# TC37XPD register map
Vendor: Infineon; Series: ATVMC; File version: 100
CPU: other r0p0, little endian, MPU, FPU, vendor SysTick, 4 interrupt priority bits
Registers are 32-bit, read-write, reset 0x0 unless marked. A register's access mark holds for its fields unless they carry their own. Offsets are from the block's base; [hi:lo] are bit positions; {n}, {i} and the like mark numbered series.

## PMS (part 1 of 3)
Base 0xF0248000
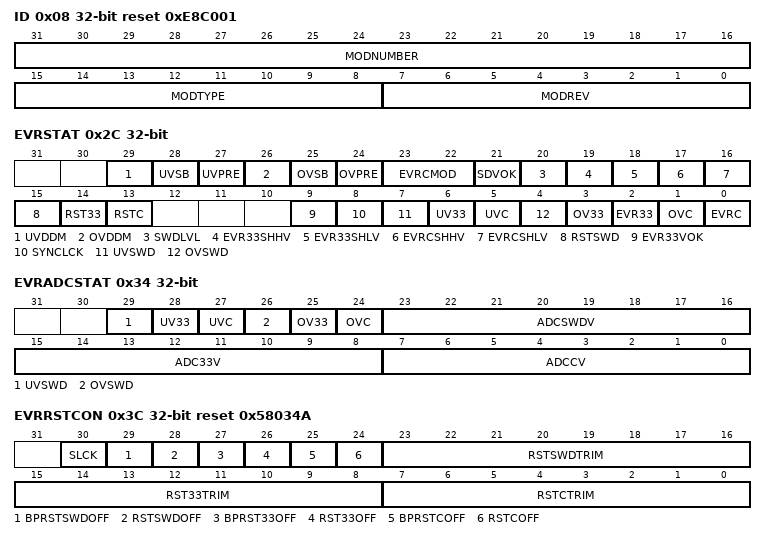
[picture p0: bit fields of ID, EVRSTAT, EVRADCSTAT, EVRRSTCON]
0x08 ID ro reset 0xE8C001 — Identification Register resetvalue={Application Reset:0x0E8C001}
  [31:16] MODNUMBER — Module Number MODNUMBER. This bit field defines the module identification number. The identification number for the PMS is 00E8 H .
  [15:8] MODTYPE — Module Type MODTYPE. This bit field is fixed coded as C0 H . It defines a 32 bit module.
  [7:0] MODREV — Module Revision Number MODREV. This bit field indicates the revision number of the PMS module. This is intended as a continuous numbering scheme defined by Design.
0x2C EVRSTAT ro — EVR Status Register resetvalue={LVD Reset:0x0,Cold PORST:0x0}
  [29] UVDDM — ADC VDDM Supply Under voltage event flag UVDDM. This bit is set if VDDM ADC supply secondary voltage monitor recognizes an under voltage event. An alarm is raised to the SMU.
  [28] UVSB — Standby Supply or VEVRSB Under voltage event flag UVSB. This bit is set if VEVRSB supply secondary voltage monitor recognizes an under voltage event. An alarm is raised to the SMU.
  [27] UVPRE — Pre Regulator VDDPD Under voltage event flag UVPRE. This bit is set if VDDPD supply secondary voltage monitor recognizes an under voltage event. An alarm is raised to the SMU.
  [26] OVDDM — ADC VDDM Supply Over voltage event flag OVDDM. This bit is set if VDDM ADC supply secondary voltage monitor recognizes an over voltage event. An alarm is raised to the SMU.
  [25] OVSB — Standby Supply or VEVRSB Over voltage event flag OVSB. This bit is set if VEVRSB supply secondary voltage monitor recognizes an over voltage event. An alarm is raised to the SMU.
  [24] OVPRE — Pre Regulator VDDPD Over voltage event flag OVPRE. This bit is set if VDDPD supply secondary voltage monitor recognizes an over voltage event. An alarm is raised to the SMU.
  [23:22] EVRCMOD — EVRC Mode EVRCMOD. This bit indicates the current operation mode of LC PWM LPM STRT. Depending on whether EVRC is activated the status bit is consequently updated. status mode o
  [21] SDVOK — EVRC Regulator Voltage OK status SDVOK. This bit is set by the EVRC voltage OK detector to indicate that the new regulator output value has been reached. This bit is reset incase EVRTRIM. SDVOUTSEL or SDVOUTTRIM values are adapted to scale core voltage and is set when the new output setpoint is reached. This bit is also reset incase droop compensation is requested before a load jump event. A time out period of x 160 us shall be waited when polling SDVOK bit. status voltok o
  [20] SWDLVL — VEXT External Supply Level Status SWDLVL. This bit indicates that the VEXT voltage has dropped below 4 160 V to indicate EVRC parameter switch to differentiate 5V or 3.3V external supply. A hysteresis of 120 160 mV is implemented on this detector. drv low vdd . The primary SWD ADC monitor value is used for EVRC SWDLVL comparator.
  [19] EVR33SHHV — Short to supply EVR33SHHV. This bit is set if a short condition to supply has been detected. The measured EVR33 output exceeds the allowed supply range and the upper gate drive threshold voltage driving P ch. MOSFET VGATEL 4 9V is reached.
  [18] EVR33SHLV — Short to ground EVR33SHLV. This bit is set if a short condition to ground has been detected. The measured EVR33 output is below the operational supply range and the lower gate drive threshold voltage driving P ch. MOSFET VGATEL 0 1V is reached.
  [17] EVRCSHHV — Short to supply EVRCSHHV. This bit is set if a short condition to supply has been detected. The measured EVRC output exceeds the allowed supply range and the lower controller limits are reached. The feature is supported only during closed loop operation or EVRCMOD 160 160 00b. evr sd short to hv
  [16] EVRCSHLV — Short to ground EVRCSHLV. This bit is set if a short condition to ground has been detected. The measured EVRC output is below the operational supply range and the upper controller limits are reached.The feature is supported only during closed loop operation or EVRCMOD 160 160 00b. evr sd short to lv
  [15] RSTSWD — EVR SWD Reset Trigger RSTSWD
  [14] RST33 — EVR33 Reset Trigger RST33
  [13] RSTC — EVRC Reset Trigger RSTC
  [9] EVR33VOK — EVR33 Regulator Voltage OK status EVR33VOK. This bit is set after the soft ramp up time of the EVR33 voltage OK ramp detector has elapsed and is not based on the measured VDDP3 voltage at the end of ramp phase..
  [8] SYNCLCK — EVRC Synchronization Input Locked status sd sync in locked o SYNCLCK. This bitfield indicates the current synchronization status of EVRC SMPS regulator to external DCDCSYNCI input signal. When the EVRC switching frequency edge is locked to the synchronization input the SYNCLCK bit is set to HIGH indicating the locked state. When the synchronization is lost owing to frequency deviations beyond MAXDEV or the feature is disabled via SYNCEN the SYNCLCK bit is set to LOW. This EVRC Synchronization status is indicated in EVRSDSTAT0.SYNCLCK status bits.
  [7] UVSWD — VEXT Under voltage event flag UVSWD. This bit is set if VEXT secondary voltage monitor recognizes an under voltage event. An alarm is raised to the SMU and the status bit remains set until violation disappears.
  [6] UV33 — VDDP3 Under voltage event flag UV33. This bit is set if VDDP3 secondary voltage monitor recognizes a under voltage event. An alarm is raised to the SMU and the status bit remains set until violation disappears.
  [5] UVC — VDD Under voltage event flag UVC. This bit is set if VDD secondary voltage monitor recognizes a under voltage event. An alarm is raised to the SMU and the status bit remains set until violation disappears.
  [4] OVSWD — VEXT Over voltage event flag OVSWD. This bit is set if VEXT secondary voltage monitor recognizes an over voltage event. An alarm is raised to the SMU and the status bit remains set until violation disappears.
  [3] OV33 — VDDP3 Over voltage event flag OV33. This bit is set if VDDP3 secondary voltage monitor recognizes a over voltage event. An alarm is raised to the SMU and the status bit remains set until violation disappears.
  [2] EVR33 — EVR33 status EVR33. This bit is set if the internal EVR33 LDO regulator is active. EVR33 is activated if HWCFG 1 pin level is latched high during start up phase. The bit reflects the EVR33 enable bit provided from PMS to PID.
  [1] OVC — VDD Over voltage event flag OVC. This bit is set if VDD secondary voltage monitor recognizes a over voltage event. An alarm is raised to the SMU and the status bit remains set until violation disappears.
  [0] EVRC — EVRC status EVRC. This bit is set if the internal EVRC regulator is currently active. EVRC is activated if HWCFG 2 pin level is latched high during start up phase. The bit reflects the DCDC regulator enable bit provided from PMS to DCDC.
0x34 EVRADCSTAT ro — EVR Primary ADC Status Register resetvalue={LVD Reset:0x0}
  [29] UVSWD — Supply Watchdog SWD or VEXT Under voltage event flag UVSWD. This bit is set if VEXT primary voltage monitor recognizes an under voltage event. An alarm is raised to the HSM and SMU.
  [28] UV33 — EVR33 Regulator or VDDP3 Under voltage event flag UV33. This bit is set if VDDP3 primary voltage monitor recognizes a under voltage event. An alarm is raised to the HSM and SMU.
  [27] UVC — EVRC Regulator or VDD Under voltage event flag UVC. This bit is set if VDD primary voltage monitor recognizes a under voltage event. An alarm is raised to the HSM and SMU.
  [26] OVSWD — Supply Watchdog SWD or VEXT Over voltage event flag OVSWD. This bit is set if VEXT primary voltage monitor recognizes an over voltage event. An alarm is raised to the HSM and SMU.
  [25] OV33 — EVR33 Regulator or VDDP3 Over voltage event flag OV33. This bit is set if VDDP3 primary voltage monitor recognizes a over voltage event. An alarm is raised to the HSM and SMU.
  [24] OVC — EVRC Regulator or VDD Over voltage event flag OVC. This bit is set if VDD primary voltage monitor recognizes a over voltage event. An alarm is raised to the HSM and SMU.
  [23:16] ADCSWDV — ADC VEXT Supply Conversion Result ADCSWDV. This bit field contains the last filtered conversion result of the ADC measurement of the external VEXT 3.3V xa0 xa0 5V supply by the Primary Monitor. VIN xa0 xa0 1.050 ADCSWDV xa0 xa0 LSB xa0 V xa0 LSB 20 xa0 mV Eg. 5 V C6
  [15:8] ADC33V — ADC VDDP3 Voltage Conversion Result ADC33V. This bit field contains the last filtered conversion result of the ADC measurement of the VDDP3 xa0 xa0 EVR33 supply by the Primary Monitor. VIN xa0 xa0 0.9375 ADC33V xa0 xa0 LSB xa0 V LSB 15 xa0 mV Eg. 3.3 V 9E
  [7:0] ADCCV — ADC VDD Core Voltage Conversion Result ADCCV. This bit field contains the last filtered conversion result of the ADC measurement of the VDD xa0 xa0 EVRC supply by the Primary Monitor. VIN xa0 xa0 0.7125 ADCCV xa0 xa0 LSB xa0 V LSB 5 xa0 mV Eg. 1.25 V 6C
0x3C EVRRSTCON access per field reset 0x58034A (reset mask 0xFFFA03FE) — EVR Reset Control Register resetvalue={LVD Reset:0x597F4A,Cold PORST:0x597F4A,After SSW execution:0x5C834B}
  [30] SLCK rw — HSM Security Lock SLCK. If this bit is set all other bits in this register can no longer be written. Write requests to other bits when SLCK is set will trigger an SLCK access error alarm.This bit can not by cleared by software. SLCK bit can only be set by an access from the HSM master TAG 160 160 000011 B . A set operation performed by any other master or software is ignored and the bit is kept as cleared.
  [29] BPRSTSWDOFF wo — Bit Protection RSTSWDOFF BPRSTSWDOFF. Setting this bit enables that bit RSTSWDOFF can be changed in this write operation. This bit is read as zero.
  [28] RSTSWDOFF rw — VEXT Reset Enable RSTSWDOFF. This bit can only be changed if bit BPRSTSWDOFF is set in parallel. RSTSWDOFF is intended to be used only for internal test purposes and the primary reset generation is not to be disabled in customer application.
  [27] BPRST33OFF wo — Bit Protection RST33OFF BPRST33OFF. Setting this bit enables that bit RST33OFF can be changed in this write operation. This bit read also as zero.
  [26] RST33OFF rw — VDDP3 Reset Enable RST33OFF. This bit can only be changed if bit BPRST33OFF is set in parallel. The VDDP3 reset is disabled by application to support voltage drop up to nominal 3.0 160 V during cranking. RST33OFF is intended to be used only for internal test purposes and the primary reset generation is not to be disabled in customer application.
  [25] BPRSTCOFF wo — Bit Protection RSTCOFF BPRSTCOFF. Setting this bit enables that bit RSTCOFF can be changed in this write operation. This bit is read as zero.
  [24] RSTCOFF rw — VDD Reset Enable RSTCOFF. This bit can only be changed if bit BPRSTCOFF is set in parallel. RSTCOFF is intended to be used only for internal test purposes and the primary reset generation is not to be disabled in customer application.
  [23:16] RSTSWDTRIM rw — VEXT Supply Reset Trim Value RSTSWDTRIM. This bit field selects the hard reset generation level of the external VEXT supply rail. This bitfield is trimmed by Firmware. RSTSWDTRIM VDDx 1050 mV LSB if RSTSWDPTRIM 0 VEXTPRIUV 1050 mV LSB RSTSWDTRIM LSB RSTSWDPTRIM signed value LSB 20 mV
  [15:8] RST33TRIM rw — VDDP3 Supply Reset Trim Value RST33TRIM. This bit field selects the hard reset generation level of VDDP3 supply rail. This bit field is trimmed by Firmware. RST33TRIM VDDx 937.5 mV LSB if RST33PTRIM 0 VDDP3PRIUV 160 160 937.5 mV LSB RST33TRIM LSB RST33PTRIM signed value LSB 15 mV
  [7:0] RSTCTRIM rw — VDD Supply Reset Trim Value RSTCTRIM. This bit field selects the hard reset generation level of VDD supply rail. This bit field is trimmed by Firmware. RSTCTRIM 160 160 VDDx 712.5 mV LSB if RSTCPTRIM 0 VDDPRIUV 160 160 712.5 mV LSB RSTCTRIM LSB RSTCPTRIM signed value LSB 5 mV
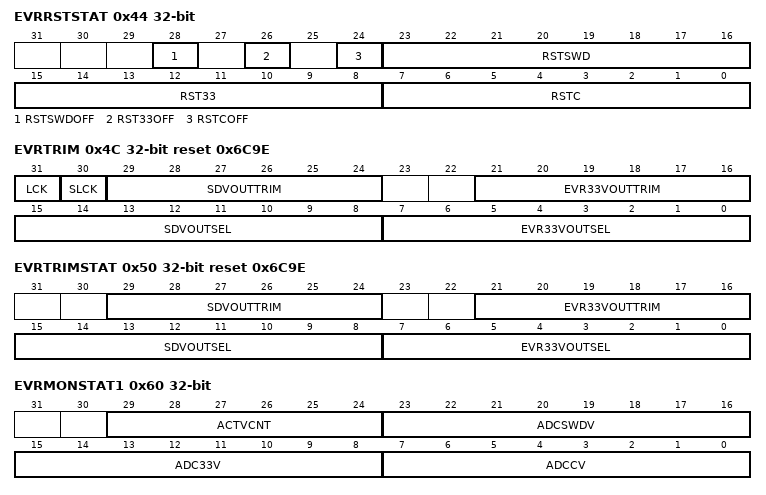
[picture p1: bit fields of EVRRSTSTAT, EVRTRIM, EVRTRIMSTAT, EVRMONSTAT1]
0x44 EVRRSTSTAT ro — EVR Reset Status Register resetvalue={LVD Reset:0x0,Cold PORST:0x0}
  [28] RSTSWDOFF — EVR SWD Reset Enable RSTSWDOFF. The value is updated via PMS EVRRSTCON .RSTSWDOFF register bit.
  [26] RST33OFF — EVR33 Reset Enable Status RST33OFF. The value is updated via PMS EVRRSTCON .RST33OFF register bit.
  [24] RSTCOFF — EVRC Reset Enable Status RSTCOFF. The value is updated via PMS EVRRSTCON .RSTCOFF register bit.
  [23:16] RSTSWD — VEXT Supply Reset Value Status RSTSWD. This bit field indicates the actual cold PORST reset trim setpoint for 5 160 V supply rail used by the Primary monitors. The value is updated via PMS EVRRSTCON .RSTSWDTRIM and PMS EVRRSTCON2 . RSTSWDPTRIM register. RSTSWD RSTSWDTRIM RSTSWDPTRIM signed value RSTSWD range 160 160 0 up to 255 VEXTPRIUV 1050 mV LSB RSTSWD LSB 20 mV
  [15:8] RST33 — VDDP3 Supply Reset Value Status RST33. This bit field indicates the actual cold PORST reset trim setpoint for 3.3 160 V supply rail used by the Primary monitors. The value is updated via PMS EVRRSTCON .RST33TRIM and PMS EVRRSTCON2 .RST33PTRIM register. RST33 RST33TRIM RST33PTRIM signed value RST33 range 160 160 0 up to 255 VDDP3PRIUV 937.5 mV LSB RST33 LSB 15 mV
  [7:0] RSTC — VDD Supply Reset Value Status RSTC. This bit field indicates the actual cold PORST reset trim setpoint for core voltage supply rail used by the Primary monitors. The value is updated via PMS EVRRSTCON .RSTCTRIM and PMS EVRRSTCON2 .RSTCPTRIM register. RSTC RSTCTRIM RSTCPTRIM signed value RSTC range 160 160 0 up to 255 VDDPRIUV 712.5 mV LSB RSTC LSB 5 mV
0x4C EVRTRIM access per field reset 0x6C9E (reset mask 0x7FFFFFFF) — EVR Trim Control Register resetvalue={LVD Reset:0x080006C9E,Cold PORST:0x080006C9E,After SSW execution:0x6C9E}
  [31] LCK ro — Lock Status LCK. This bit indicates if the register can be updated with a new value or if the register is locked and a write action from the bus side has no effect. When EVRSDCTRL0.UP bit is set to 1 register is locked for shadow register update and LCK bit is set to 1. Once shadow register update is done the lock is released and LCK bit is set to 0.
  [30] SLCK rw — HSM Security Lock SLCK. If this bit is set all other bits in this register can no longer be written. Write requests to other bits when SLCK is set will trigger an SLCK access error alarm.This bit can not by cleared by software. SLCK bit can only be set by an access from the HSM master TAG 160 160 000011 B . A set operation performed by any other master or software is ignored and the bit is kept as cleared.
  [29:24] SDVOUTTRIM rw — EVRC Regulator Output Voltage Trim Value vtrim trim i SDVOUTTRIM. The 6 bit ADC BIST trimming value offset added to the EVRC output level value installed by firmware from the flash. The reaching of the new setpoint is indicated via EVRSTAT.SDVOK bits VDD Setpoint SDVOUTSEL SDVOUTTRIM signed value SDVOUTTRIM RANGE 32 to 31 LSB LSB 5 mV This register bitfield requires a parameter update via EVRSDCTRL0.UP for transfer to SMPS shadow register.
  [21:16] EVR33VOUTTRIM rw — EVR33 Regulator Output Voltage Trim Value EVR33VOUTTRIM. The 6 bit ADC BIST trimming value offset added to the EVR33 output level value installed by firmware from the flash. This field is meant for trimming during production tests. VDDP3 Setpoint EVR33VOUTSEL EVR33VOUTTRIM signed value EVR33OUTTRIM RANGE 32 to 31 LSB LSB 15 mV
  [15:8] SDVOUTSEL rw — EVRC Regulator Output Voltage Target Value SDVOUTSEL. The VDD output level of the Step down regulator. vosel target i 1.25 V 6C 108 SDVOUTSEL VDD 712.5 mV LSB VDD 712.5 mV LSB SDVOUTSEL LSB 5 mV. This register bitfield requires a parameter update via EVRSDCTRL0.UP for transfer to EVRC SMPS shadow register. The reaching of the new target value is indicated via EVRSTAT.SDVOK bit.
  [7:0] EVR33VOUTSEL rw — EVR33 Regulator Output Voltage Target Value EVR33VOUTSEL. The VDDP3 output level of the EVR33 LDO regulator. The ramp up completion to the new target value is indicated via EVRSTAT.EVR33VOK bit. The EVR33VOUTSEL EVR33VOUTTRIM setpoint value shall be programmed between 0x24 and 0xDA for valid closed loop PID regulator function. 3.3 V 9E 158 EVR33VOUTSEL VDDP3 937.5 mV LSB VDDP3 937.5 mV LSB EVR33VOUTSEL LSB 15 mV
0x50 EVRTRIMSTAT ro reset 0x6C9E — EVR Trim Status Register resetvalue={LVD Reset:0x6C9E,Cold PORST:0x6C9E}
  [29:24] SDVOUTTRIM — EVRC Regulator Output Voltage Trim Value vtrim trim o SDVOUTTRIM. This bit field indicates the 5 bit ADC BIST trimming value offset added to the EVRC output level value installed by firmware from flash configuration sector as configured in EVTRIM.SDVOUTTRIM.
  [21:16] EVR33VOUTTRIM — EVR33 Regulator Output Voltage Trim Value EVR33VOUTTRIM. This bit field indicates the 6 bit ADC BIST trimming value offset added to the EVR33 output level value installed by firmware from flash configuration sector if production trimming is required.
  [15:8] SDVOUTSEL — EVRC Regulator Output Voltage Target Value SDVOUTSEL. This bit field indicates the EVRC output level of the Step down regulator as configured in EVTRIM.SDVOUTSEL. vosel target o
  [7:0] EVR33VOUTSEL — EVR33 Regulator Output Voltage Target Value EVR33VOUTSEL. This bitfield indicates EVR33 output target value as configured in EVTRIM.EVR33VOUTSEL.
0x60 EVRMONSTAT1 ro — EVR Secondary ADC Status Register 1 resetvalue={LVD Reset:0x0,Cold PORST:0x0}
  [29:24] ACTVCNT — Secondary Monitor Activity Counter ACTVCNT. This bit field cumulatively counts the end of conversion signals in a single Secondary Monitor Background Scan over all channels and respective filter configurations. The total number of conversions ConvTot 8721 ChX ChXFIL . The counter is reset to 0 on a ConvTot overflow.
  [23:16] ADCSWDV — VEXT Supply Secondary ADC Conversion Result ADCSWDV. This bit field contains the last conversion result of the ADC measurement of the external VEXT 3.3V 160 160 5V supply by the Secondary Monitor. This bitfield is updated if secondary over or under voltage monitoring is activated via EVRMONCTRL.SWDxxMOD. The update of the result is taking place at 6 160 160 160 12 160 160 active channels 160 160 fBACK 4 160 clock cycles. VIN 160 160 LSB 160 160 ADCx 1 160 160 LSB 23.077 160 mV Full Range 160 160 5861 160 mV E.g. 5.01 160 V DA 160 160 160 160 160 160 3.3 160 V 90
  [15:8] ADC33V — VDDP3 Supply Secondary ADC Conversion Result ADC33V. This bit field contains the last conversion result of the ADC measurement of the VDDP3 160 160 EVR33 supply by the Secondary Monitor. This bitfield is updated if secondary over or under voltage monitoring is activated via EVRMONCTRL.EVR33xxMOD. The update of the result is taking place at 6 160 160 160 12 160 160 active channels 160 160 fBACK 4 160 clock cycles. VIN 160 160 LSB 160 160 ADCx 1 160 160 Ideal LSB 15.00 160 mV Full Range 160 160 3810 160 mV E.g. 3.30 160 V DD
  [7:0] ADCCV — VDD Supply Secondary ADC Conversion Result ADCCV. This bit field contains the last conversion result of the ADC measurement of the VDD 160 160 EVRC supply by the Secondary Monitor. This bitfield is updated if secondary over or under voltage monitoring is activated via EVRMONCTRL.EVRCxxMOD. The update of the result is taking place at 6 160 160 160 12 160 160 active channels 160 160 fBACK 4 160 clock cycles. VIN 160 160 LSB 160 160 ADCx 1 160 160 Ideal LSB 5.7692 160 mV Full Range 160 160 1465 160 mV E.g. 1.25 160 V DA
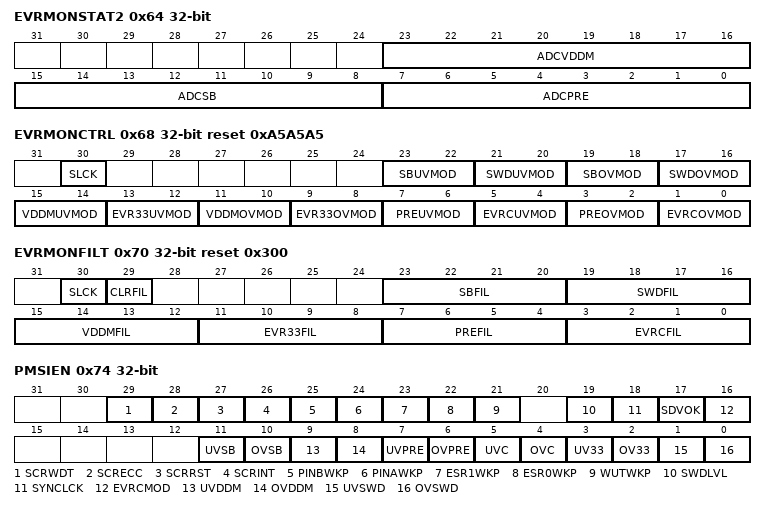
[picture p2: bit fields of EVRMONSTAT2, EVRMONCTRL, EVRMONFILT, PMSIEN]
0x64 EVRMONSTAT2 ro — EVR Secondary ADC Status Register 2 resetvalue={LVD Reset:0x0,Cold PORST:0x0}
  [23:16] ADCVDDM — VDDM Supply Secondary ADC Conversion Result ADCVDDM. This bit field contains the last conversion result of the ADC measurement of the VDDM ADC supply by the Secondary Monitor. This bitfield is updated if secondary over or under voltage monitoring is activated via EVRMONCTRL.VDDMxxMOD. The update of the result is taking place at 6 160 160 160 12 160 160 active channels 160 160 fBACK 4 160 clock cycles. VIN 160 160 LSB 160 160 ADCx 1 160 160 Ideal LSB 23.077 160 mV Full Range 160 160 5861 160 mV E.g. 5.01 160 V DA 160 160 160 160 160 160 3.0 160 V 90
  [15:8] ADCSB — VEVRSB Supply Secondary ADC Conversion Result ADCSB. This bit field contains the last conversion result of the ADC measurement of the external VEVRSB 3.3V 160 160 5V standby supply by the Secondary Monitor. This bitfield is updated if secondary over or under voltage monitoring is activated via EVRMONCTRL.SBxxMOD. The update of the result is taking place at 6 160 160 160 12 160 160 active channels 160 160 fBACK 4 160 clock cycles. VIN 160 160 LSB 160 160 ADCx 1 160 160 Ideal LSB 23.077 160 mV Full Range 160 160 5861 160 mV E.g. 5.01 160 V DA 160 160 160 160 160 160 3.0 160 V 90
  [7:0] ADCPRE — VDDPD Supply Secondary ADC Conversion Result ADCPRE. This bit field contains the last conversion result of the ADC measurement of the VDDPD supply by the Secondary Monitor. This bitfield is updated if secondary over or under voltage monitoring is activated via EVRMONCTRL.PRExxMOD. The update of the result is taking place at 6 160 160 160 12 160 160 active channels 160 160 fBACK 4 160 clock cycles. VIN 160 160 LSB 160 160 ADCx 1 160 160 Ideal LSB 5.7692 160 mV Full Range 160 160 1465 160 mV E.g. 1.25 160 V DA
0x68 EVRMONCTRL reset 0xA5A5A5 — EVR Secondary Monitor Control Register resetvalue={LVD Reset:0x0A5A5A5,Cold PORST:0x0A5A5A5,After SSW execution:0x0A5A5A5}
  [30] SLCK — HSM Security Lock SLCK. If this bit is set all other bits in this register can no longer be written. Write requests to other bits when SLCK is set will trigger an SLCK access error alarm.This bit can not by cleared by software. SLCK bit can only be set by an access from the HSM master TAG 160 160 000011 B . A set operation performed by any other master or software is ignored and the bit is kept as cleared.
  [23:22] SBUVMOD — EVR Standby Supply or VEVRSB Under voltage monitoring mode SBUVMOD. Incase both SBOVMOD 160 160 00 amp SBUVMOD 160 160 00 then ADC conversion for the respective supply rail does not take place.
  [21:20] SWDUVMOD — VEXT Under voltage monitoring mode SWDUVMOD. Incase both SWDOVMOD 160 160 00 amp SWDUVMOD 160 160 00 then ADC conversion for the respective supply rail does not take place.
  [19:18] SBOVMOD — EVR Standby Supply or VEVRSB Over voltage monitoring mode SBOVMOD. Incase both SBOVMOD 160 160 00 amp SBUVMOD 160 160 00 then ADC conversion for the respective supply rail does not take place.
  [17:16] SWDOVMOD — VEXT Over voltage monitoring mode SWDOVMOD. Incase both SWDOVMOD 160 160 00 amp SWDUVMOD 160 160 00 then ADC conversion for the respective supply rail does not take place.
  [15:14] VDDMUVMOD — VDDM ADC Supply Under voltage monitoring mode VDDMUVMOD. Incase both VDDMOVMOD 160 160 00 amp VDDMUVMOD 160 160 00 then ADC conversion for the VDDM supply rail continues to run as used for ADC function.
  [13:12] EVR33UVMOD — VDDP3 Supply Under voltage monitoring mode EVR33UVMOD. Incase both EVR33OVMOD 160 160 00 amp EVR33UVMOD 160 160 00 then ADC conversion for the respective supply rail does not take place.
  [11:10] VDDMOVMOD — VDDM ADC Supply Over voltage monitoring mode VDDMOVMOD. Incase both VDDMOVMOD 160 160 00 amp VDDMUVMOD 160 160 00 then ADC conversion for the VDDM supply rail continues to run as used for ADC function.
  [9:8] EVR33OVMOD — VDDP3 Supply Over voltage monitoring mode EVR33OVMOD. Incase both EVR33OVMOD 160 160 00 amp EVR33UVMOD 160 160 00 then ADC conversion for the respective supply rail does not take place.
  [7:6] PREUVMOD — EVRPR or VDDPD Under voltage monitoring mode PREUVMOD. Incase both PREOVMOD 160 160 00 amp PREUVMOD 160 160 00 then ADC conversion for the respective supply rail does not take place.
  [5:4] EVRCUVMOD — VDD Under voltage monitoring mode EVRCUVMOD. Incase both EVRCOVMOD 160 160 00 amp EVRCUVMOD 160 160 00 then ADC conversion for the respective supply rail does not take place.
  [3:2] PREOVMOD — EVRPR or VDDPD Over voltage monitoring mode PREOVMOD. Incase both PREOVMOD 160 160 00 amp PREUVMOD 160 160 00 then ADC conversion for the respective supply rail does not take place.
  [1:0] EVRCOVMOD — VDD Over voltage monitoring mode EVRCOVMOD. Incase both EVRCOVMOD 160 160 00 amp EVRCUVMOD 160 160 00 then ADC conversion for the respective supply rail does not take place.
0x70 EVRMONFILT reset 0x300 (reset mask 0xFFFEFFFE) — EVR Secondary Monitor Filter Register resetvalue={LVD Reset:0x300,Cold PORST:0x300,After SSW execution:0x10301}
  [30] SLCK — HSM Security Lock SLCK. If this bit is set all other bits in this register can no longer be written. Write requests to other bits when SLCK is set will trigger an SLCK access error alarm.This bit can not by cleared by software. SLCK bit can only be set by an access from the HSM master TAG 160 160 000011 B . A set operation performed by any other master or software is ignored and the bit is kept as cleared.
  [29] CLRFIL — Clear all Spike Filters CLRFIL. To avoid spurious alarms during change of configuration or start up CLRFIL shall be set followed by alarm reconfiguration followed by activation of filter logic by clearing CLRFIL register bit.
  [23:20] SBFIL — VEVRSB Secondary ADC Supply Filter SBFIL
  [19:16] SWDFIL — VEXT Secondary ADC Supply Filter SWDFIL
  [15:12] VDDMFIL — VDDM Secondary ADC Supply Filter VDDMFIL
  [11:8] EVR33FIL — VDDP3 Secondary ADC Supply Filter EVR33FIL
  [7:4] PREFIL — VDDPD Secondary ADC Supply Filter PREFIL
  [3:0] EVRCFIL — VDD Secondary ADC Supply Filter EVRCFIL
0x74 PMSIEN — PMS Interrupt Enable Register resetvalue={LVD Reset:0x0,Cold PORST:0x0}
  [29] SCRWDT — SCRWDT Interrupt enable SCRWDT. Interrupt triggered by SCR to PMS on an internal SCR watchdog timeout error.
  [28] SCRECC — SCRECC Interrupt enable SCRECC. Interrupt triggered by SCR to PMS on an internal RAM double bit ECC error.
  [27] SCRRST — SCRRST Interrupt enable SCRRST. Interrupt triggered by SCR to PMS on an internal SCR software reset.
  [26] SCRINT — SCRINT Interrupt enable SCRINT. Interrupt triggered on a SCRINT event triggered by SCR to PMS to decode information in PMSWCR2.SCRINT register.
  [25] PINBWKP — PINBWKP Interrupt enable PINBWKP. Interrupt triggered on a PINBWKP event.
  [24] PINAWKP — PINAWKP Interrupt enable PINAWKP. Interrupt triggered on a PINAWKP event.
  [23] ESR1WKP — ESR1WKP Interrupt enable ESR1WKP. Interrupt triggered on a ESR1WKP event.
  [22] ESR0WKP — ESR0WKP Interrupt enable ESR0WKP. Interrupt triggered on a ESR0WKP event.
  [21] WUTWKP — WUTWKP Interrupt enable WUTWKP. Interrupt triggered on a WUTCNT underflow event.
  [19] SWDLVL — SWDLVL Interrupt enable SWDLVL. Interrupt triggered on a state change of EVRSTAT.SWDLVL bitfield.
  [18] SYNCLCK — SD SYNCLCK Interrupt enable SYNCLCK. Interrupt triggered on a state change of EVRSTAT.SYNCLCK bitfield.
  [17] SDVOK — SDVOK Interrupt enable SDVOK. Interrupt triggered on EVRSTAT.SDVOK rising edge event.
  [16] EVRCMOD — EVRCMOD Interrupt enable EVRCMOD. Interrupt triggered on a state change of EVRSTAT.EVRCMOD 0 bitfield.
  [11] UVSB — UVSB Interrupt enable UVSB. Interrupt triggered on event as configured in EVRMONCTRL register.
  [10] OVSB — OVSB Interrupt enable OVSB. Interrupt triggered on event as configured in EVRMONCTRL register.
  [9] UVDDM — UVDDM Interrupt enable UVDDM. Interrupt triggered on event as configured in EVRMONCTRL register.
  [8] OVDDM — OVDDM Interrupt enable OVDDM. Interrupt triggered on event as configured in EVRMONCTRL register.
  [7] UVPRE — UVPRE Interrupt enable UVPRE. Interrupt triggered on event as configured in EVRMONCTRL register.
  [6] OVPRE — OVPRE Interrupt enable OVPRE. Interrupt triggered on event as configured in EVRMONCTRL register.
  [5] UVC — UVC Interrupt enable UVC. Interrupt triggered on event as configured in EVRMONCTRL register.
  [4] OVC — OVC Interrupt enable OVC. Interrupt triggered on event as configured in EVRMONCTRL register.
  [3] UV33 — UV33 Interrupt enable UV33. Interrupt triggered on event as configured in EVRMONCTRL register.
  [2] OV33 — OV33 Interrupt enable OV33. Interrupt triggered on event as configured in EVRMONCTRL register.
  [1] UVSWD — UVSWD Interrupt enable UVSWD. Interrupt triggered on event as configured in EVRMONCTRL register.
  [0] OVSWD — OVSWD Interrupt enable OVSWD. Interrupt triggered on event as configured in EVRMONCTRL register.
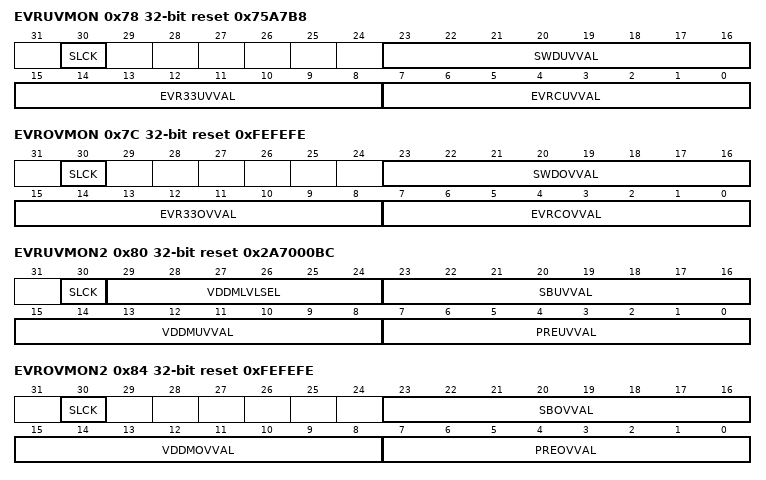
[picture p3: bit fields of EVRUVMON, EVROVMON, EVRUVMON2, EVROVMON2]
0x78 EVRUVMON reset 0x75A7B8 — EVR Secondary Under voltage Monitor Register resetvalue={LVD Reset:0x75A7B8,Cold PORST:0x75A7B8,After SSW execution:0x75A7B8}
  [30] SLCK — HSM Security Lock SLCK. If this bit is set all other bits in this register can no longer be written. Write requests to other bits when SLCK is set will trigger an SLCK access error alarm.This bit can not by cleared by software. SLCK bit can only be set by an access from the HSM master TAG 160 160 000011 B . A set operation performed by any other master or software is ignored and the bit is kept as cleared.
  [23:16] SWDUVVAL — VEXT Supply Secondary Monitor Under voltage threshold SWDUVVAL. This field defines the under voltage threshold level of the external VEXT supply monitor. Ideal Threshold VIN 160 160 LSB 160 160 1 Ideal LSB 23.077 160 mV.
  [15:8] EVR33UVVAL — VDDP3 Supply Secondary Monitor Under voltage threshold EVR33UVVAL. This field defines the under voltage monitoring threshold level of the EVR33 regulator output or VDDP3 supply. Ideal Threshold VIN 160 160 LSB 160 160 1 . Ideal LSB 15.00 160 mV
  [7:0] EVRCUVVAL — VDD Supply Secondary Monitor Under voltage threshold EVRCUVVAL. This field defines the under voltage monitoring threshold level of the EVRC regulator output or VDD supply. Ideal Threshold VIN 160 160 LSB 160 160 1 Ideal LSB 5.7692 160 mV
0x7C EVROVMON reset 0xFEFEFE — EVR Secondary Over voltage Monitor Register resetvalue={LVD Reset:0x0FEFEFE,Cold PORST:0x0FEFEFE,After SSW execution:0x0FEFEFE}
  [30] SLCK — HSM Security Lock SLCK. If this bit is set all other bits in this register can no longer be written. Write requests to other bits when SLCK is set will trigger an SLCK access error alarm.This bit can not by cleared by software. SLCK bit can only be set by an access from the HSM master TAG 160 160 000011 B . A set operation performed by any other master or software is ignored and the bit is kept as cleared.
  [23:16] SWDOVVAL — VEXT Supply Secondary Monitor Over voltage threshold SWDOVVAL. This field defines the over voltage threshold level of the external VEXT supply monitor. Ideal Threshold VIN 160 160 LSB 160 160 1 Ideal LSB 23.077 160 mV.
  [15:8] EVR33OVVAL — VDDP3 Supply Secondary Monitor Over voltage threshold EVR33OVVAL. This field defines the over voltage monitoring threshold level of the EVR33 regulator output or VDDP3 supply. Ideal Threshold VIN 160 160 LSB 160 160 1 Ideal LSB 15.00 160 mV
  [7:0] EVRCOVVAL — VDD Supply Secondary Monitor Over voltage threshold EVRCOVVAL. This field defines the over voltage monitoring threshold level of the EVRC regulator output or VDD supply. Ideal Threshold VIN 160 160 LSB 160 160 1 Ideal LSB 5.7692 160 mV
0x80 EVRUVMON2 reset 0x2A7000BC — EVR Secondary Under voltage Monitor Register 2 resetvalue={LVD Reset:0x2A7000BC,Cold PORST:0x2A7000BC,After SSW execution:0x2A7000BC}
  [30] SLCK — HSM Security Lock SLCK. If this bit is set all other bits in this register can no longer be written. Write requests to other bits when SLCK is set will trigger an SLCK access error alarm.This bit can not by cleared by software. SLCK bit can only be set by an access from the HSM master TAG 160 160 000011 B . A set operation performed by any other master or software is ignored and the bit is kept as cleared.
  [29:24] VDDMLVLSEL — VDDM Level Select VDDMLVLSEL. This field defines the under voltage monitoring threshold level required by EVADC 160 160 EDSADC modules to differentiate between 5 160 V or 3.3 160 V VDDM supply level to adjust analog behavior to the actual voltage level. The 6 MSB bits of the ADC result is compared against VDDMLVLSEL with 4 LSB hysteresis. Ideal Threshold VIN LSB 1 Ideal LSB 92.308 mV
  [23:16] SBUVVAL — VEVRSB Supply Secondary Monitor Under voltage threshold SBUVVAL. This field defines the under voltage threshold level of the external VEVRSB 3.3V 160 160 5V standby supply monitor. Ideal Threshold VIN 160 160 LSB 160 160 1 Ideal LSB 23.077 160 mV.
  [15:8] VDDMUVVAL — VDDM Supply Secondary Monitor Under voltage threshold VDDMUVVAL. This field defines the under voltage monitoring threshold level of the VDDM ADC supply. Ideal Threshold VIN 160 160 LSB 160 160 1 Ideal LSB 23.077 160 mV
  [7:0] PREUVVAL — VDDPD Supply Secondary Monitor Under voltage threshold PREUVVAL. This field defines the under voltage monitoring threshold level of the VDDPD supply or EVRPR output. Ideal Threshold VIN 160 160 LSB 160 160 1 Ideal LSB 5.7692 160 mV
0x84 EVROVMON2 reset 0xFEFEFE — EVR Secondary Over voltage Monitor Register 2 resetvalue={LVD Reset:0x0FEFEFE,Cold PORST:0x0FEFEFE,After SSW execution:0x0FEFEFE}
  [30] SLCK — HSM Security Lock SLCK. If this bit is set all other bits in this register can no longer be written. Write requests to other bits when SLCK is set will trigger an SLCK access error alarm.This bit can not by cleared by software. SLCK bit can only be set by an access from the HSM master TAG 160 160 000011 B . A set operation performed by any other master or software is ignored and the bit is kept as cleared.
  [23:16] SBOVVAL — VEVRSB Supply Secondary Monitor Over voltage threshold SBOVVAL. This field defines the over voltage threshold level of the external VEVRSB 3.3V 160 160 5V standby supply monitor. Ideal Threshold VIN 160 160 LSB 160 160 1 Ideal LSB 23.077 160 mV
  [15:8] VDDMOVVAL — VDDM Supply Secondary Monitor Over voltage threshold VDDMOVVAL. This field defines the over voltage monitoring threshold level of the VDDM ADC supply Ideal Threshold VIN 160 160 LSB 160 160 1 Ideal LSB 23.077 160 mV
  [7:0] PREOVVAL — VDDPD Supply Secondary Monitor Over voltage threshold PREOVVAL. This field defines the over voltage monitoring threshold level of the VDDPD supply or EVRPR output. Ideal Threshold VIN 160 160 LSB 160 160 1 Ideal LSB 5.7692 160 mV
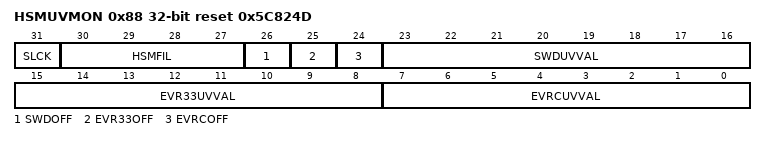
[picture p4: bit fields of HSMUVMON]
0x88 HSMUVMON reset 0x5C824D — EVR Primary HSM Under voltage Monitor Register resetvalue={LVD Reset:0x5C824D,Cold PORST:0x5C824D,After SSW execution:0x5C824D}
  [31] SLCK — HSM Security Lock SLCK. If this bit is set all other bits in this register can no longer be written. Write requests to other bits when SLCK is set will trigger an SLCK access error alarm.This bit can not by cleared by software. SLCK bit can only be set by an access from the HSM master TAG 160 160 000011 B . A set operation performed by any other master or software is ignored and the bit is kept as cleared.
  [30:27] HSMFIL — HSM Voltage Filter HSMFIL
  [26] SWDOFF — VEXT Primary Monitor UV Alarm Disable SWDOFF
  [25] EVR33OFF — VDDP3 Primary Monitor UV Alarm Disable EVR33OFF
  [24] EVRCOFF — VDD Primary Monitor UV Alarm Disable EVRCOFF
  [23:16] SWDUVVAL — VEXT Supply Primary Monitor Alarm Under voltage threshold SWDUVVAL. This field defines the under voltage threshold level of the external VEXT supply monitor. SWDUVVAL VDDx 1050 mV LSB LSB 20 mV
  [15:8] EVR33UVVAL — VDDP3 Supply Primary Monitor Alarm Under voltage threshold EVR33UVVAL. This field defines the under voltage monitoring threshold level of the EVR33 regulator output or VDDP3 supply. EVR33UVVAL VDDx 937.5 mV LSB LSB 15 mV
  [7:0] EVRCUVVAL — VDD Supply Primary Monitor Alarm Under voltage threshold EVRCUVVAL. This field defines the under voltage monitoring threshold level of the EVRC regulator output or VDD supply.EVRCUVVAL VDDx 712.5 mV LSB LSB 5 mV
